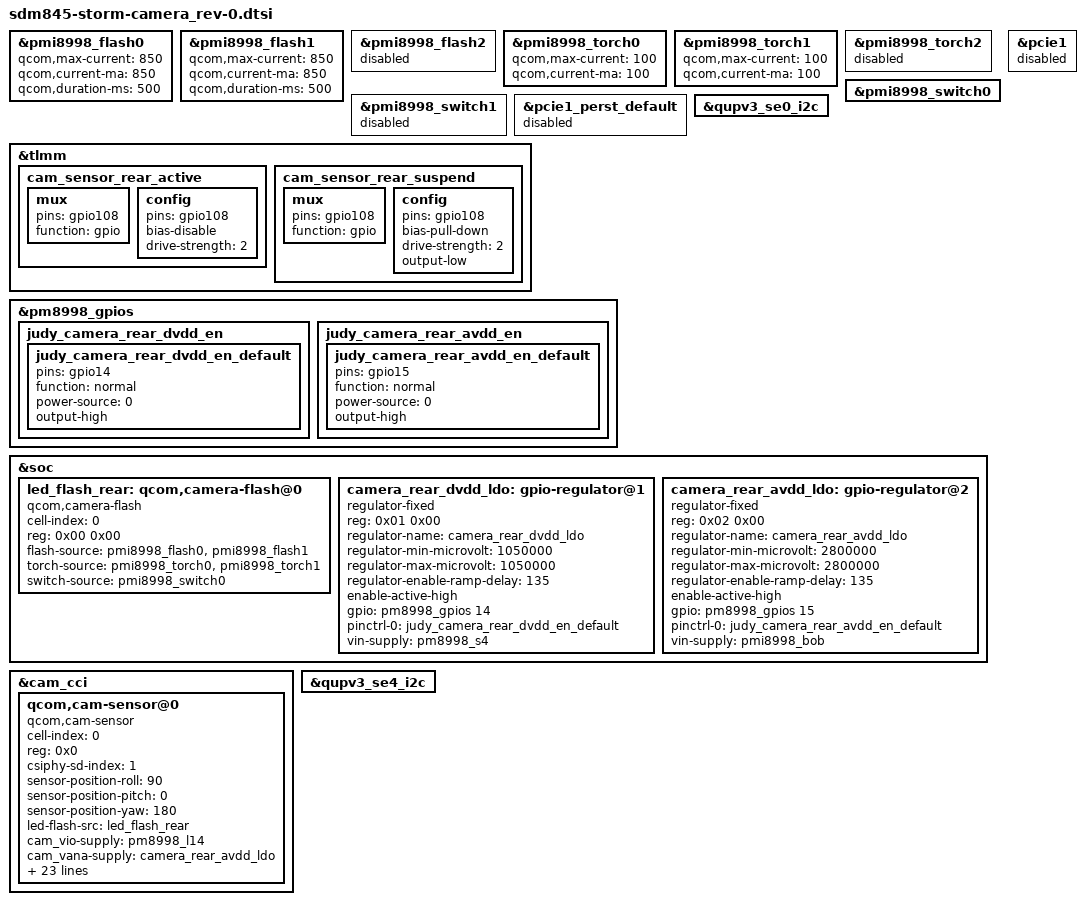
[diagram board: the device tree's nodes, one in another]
/*
 * Copyright (c) 2017 The Linux Foundation. All rights reserved.
 *
 * This program is free software; you can redistribute it and/or modify
 * it under the terms of the GNU General Public License version 2 and
 * only version 2 as published by the Free Software Foundation.
 *
 * This program is distributed in the hope that it will be useful,
 * but WITHOUT ANY WARRANTY; without even the implied warranty of
 * MERCHANTABILITY or FITNESS FOR A PARTICULAR PURPOSE.  See the
 * GNU General Public License for more details.
 */

&pmi8998_flash0 {
	status = "ok";
	qcom,max-current = <850>;
	qcom,current-ma = <850>;
	qcom,duration-ms = <500>;
};

&pmi8998_flash1 {
	status = "ok";
	qcom,max-current = <850>;
	qcom,current-ma = <850>;
	qcom,duration-ms = <500>;
};

&pmi8998_flash2 {
	status = "disabled";
};

&pmi8998_torch0 {
	status = "ok";
	qcom,max-current = <100>;
	qcom,current-ma = <100>;
};

&pmi8998_torch1 {
	status = "ok";
	qcom,max-current = <100>;
	qcom,current-ma = <100>;
};

&pmi8998_torch2 {
	status = "disabled";
};

&pmi8998_switch0 {
	status = "ok";
};

&pmi8998_switch1 {
	status = "disbled";
};

&pcie1 {
    status = "disabled";
};
&pcie1_perst_default {
    status = "disabled";
};

&qupv3_se0_i2c {
		status = "ok";
};

&tlmm{
	cam_sensor_rear_active: cam_sensor_rear_active {
		/* RESET, AVDD LDO */
		mux {
			pins = "gpio108";
			function = "gpio";
		};

		config {
			pins = "gpio108";
			bias-disable; /* No PULL */
			drive-strength = <2>; /* 2 MA */
		};
	};

	cam_sensor_rear_suspend: cam_sensor_rear_suspend {
		/* RESET, AVDD LDO */
		mux {
			pins = "gpio108";
			function = "gpio";
		};

		config {
			pins = "gpio108";
			bias-pull-down; /* PULL DOWN */
			drive-strength = <2>; /* 2 MA */
			output-low;
		};
	};
};

&pm8998_gpios {
	judy_camera_rear_dvdd_en {
		judy_camera_rear_dvdd_en_default: judy_camera_rear_dvdd_en_default {
			pins = "gpio14";
			function = "normal";
			power-source = <0>;
			output-high;
		};
	};

	judy_camera_rear_avdd_en {
		judy_camera_rear_avdd_en_default: judy_camera_rear_avdd_en_default {
			pins = "gpio15";
			function = "normal";
			power-source = <0>;
			output-high;
		};
	};
 };

&soc {
	led_flash_rear: qcom,camera-flash@0 {
		cell-index = <0>;
		reg = <0x00 0x00>;
		compatible = "qcom,camera-flash";
		flash-source = <&pmi8998_flash0 &pmi8998_flash1>;
		torch-source = <&pmi8998_torch0 &pmi8998_torch1>;
		switch-source = <&pmi8998_switch0>;
		status = "ok";
	};
	camera_rear_dvdd_ldo: gpio-regulator@1 {
		compatible = "regulator-fixed";
		reg = <0x01 0x00>;
		regulator-name = "camera_rear_dvdd_ldo";
		regulator-min-microvolt = <1050000>;
		regulator-max-microvolt = <1050000>;
		regulator-enable-ramp-delay = <135>;
		enable-active-high;
		gpio = <&pm8998_gpios 14 0>;
		pinctrl-names = "default";
		pinctrl-0 = <&judy_camera_rear_dvdd_en_default>;
		vin-supply = <&pm8998_s4>;
	};

	camera_rear_avdd_ldo: gpio-regulator@2 {
		compatible = "regulator-fixed";
		reg = <0x02 0x00>;
		regulator-name = "camera_rear_avdd_ldo";
		regulator-min-microvolt = <2800000>;
		regulator-max-microvolt = <2800000>;
		regulator-enable-ramp-delay = <135>;
		enable-active-high;
		gpio = <&pm8998_gpios 15 0>;
        pinctrl-names = "default";
        pinctrl-0 = <&judy_camera_rear_avdd_en_default>;
		vin-supply = <&pmi8998_bob>;
	};
};

&cam_cci {
	qcom,cam-sensor@0 {
		cell-index = <0>;
		compatible = "qcom,cam-sensor";
		reg = <0x0>;
		csiphy-sd-index = <1>;
		sensor-position-roll = <90>;
		sensor-position-pitch = <0>;
		sensor-position-yaw = <180>;
                led-flash-src = <&led_flash_rear>;
		cam_vio-supply = <&pm8998_l14>;
		cam_vana-supply = <&camera_rear_avdd_ldo>;
		cam_vdig-supply = <&camera_rear_dvdd_ldo>;
		cam_clk-supply = <&titan_top_gdsc>;
		regulator-names = "cam_vio", "cam_vana", "cam_vdig", "cam_clk";
		rgltr-cntrl-support;
		rgltr-min-voltage = <0 2800000 1050000 0>;
		rgltr-max-voltage = <0 2800000 1050000 0>;
		rgltr-load-current = <0 2800000 1050000 0>;
		gpio-no-mux = <0>;
		pinctrl-names = "cam_default", "cam_suspend";
		pinctrl-0 = <&cam_sensor_mclk1_active
				&cam_sensor_rear_active>;
		pinctrl-1 = <&cam_sensor_mclk1_suspend
				&cam_sensor_rear_suspend>;
		gpios = <&tlmm 14 0>,
			<&tlmm 108 0>;
		gpio-reset = <1>;
		gpio-req-tbl-num = <0 1>;
		gpio-req-tbl-flags = <1 0>;
		gpio-req-tbl-label = "CAMIF_MCLK1",
					"CAM_RESET1";
		sensor-mode = <0>;
		cci-master = <1>;
		status = "ok";
		clocks = <&clock_camcc CAM_CC_MCLK1_CLK>;
		clock-names = "cam_clk";
		clock-cntl-level = "turbo";
		clock-rates = <24000000>;
	};
};

&qupv3_se0_i2c {
        status = "ok";
};

&qupv3_se4_i2c {
        status = "ok";
};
